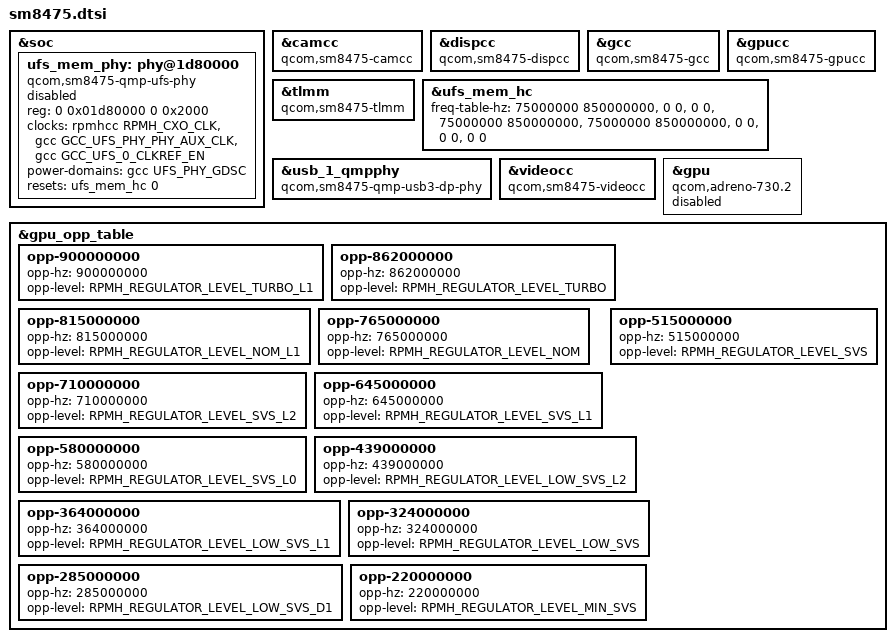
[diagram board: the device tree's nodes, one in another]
// SPDX-License-Identifier: BSD-3-Clause
/*
 * Copyright (c) 2024, Danila Tikhonov <danila@jiaxyga.com>
 *
 * Reconciled with upstream SM8450 support for Motorola Cape (SM8475).
 * Community reference: sm8450-mainline/linux bf1d29fced6e156dd6090a9b6600a8c44259c114
 * Motorola reference: kernel-devicetree 90fa7be1db5bd47202673d4431408659149a7359
 */

#include "sm8450.dtsi"

/*
 * Motorola's Cape UFS PHY is at 0x01d80000 rather than the
 * SM8450 PHY address inherited from sm8450.dtsi.
 */
/delete-node/ &ufs_mem_phy;

&soc {
	ufs_mem_phy: phy@1d80000 {
		compatible = "qcom,sm8475-qmp-ufs-phy";
		reg = <0 0x01d80000 0 0x2000>;

		clocks = <&rpmhcc RPMH_CXO_CLK>,
			 <&gcc GCC_UFS_PHY_PHY_AUX_CLK>,
			 <&gcc GCC_UFS_0_CLKREF_EN>;
		clock-names = "ref", "ref_aux", "qref";

		power-domains = <&gcc UFS_PHY_GDSC>;

		resets = <&ufs_mem_hc 0>;
		reset-names = "ufsphy";

		#clock-cells = <1>;
		#phy-cells = <0>;

		status = "disabled";
	};
};

&camcc {
	compatible = "qcom,sm8475-camcc";
};

&dispcc {
	compatible = "qcom,sm8475-dispcc";
};

&gcc {
	compatible = "qcom,sm8475-gcc";
};

&gpucc {
	compatible = "qcom,sm8475-gpucc";
};

/*
 * [INFERRED] Basic GPIO/UART muxing is compatible with SM8450.
 * Motorola's Cape pin mapping and PDC wake map were compared with the
 * upstream SM8450 driver; their complete alternate mux lists differ.
 * Keep the fallback only for initial board bring-up. Recheck before
 * enabling more pinctrl clients.
 */
&tlmm {
	compatible = "qcom,sm8475-tlmm", "qcom,sm8450-tlmm";
};

&ufs_mem_hc {
	freq-table-hz =
		<75000000 850000000>,
		<0 0>,
		<0 0>,
		<75000000 850000000>,
		<75000000 850000000>,
		<0 0>,
		<0 0>,
		<0 0>;
};

/* The baseline driver has an SM8475-specific USB3/DP PHY match. */
&usb_1_qmpphy {
	compatible = "qcom,sm8475-qmp-usb3-dp-phy";
};

&videocc {
	compatible = "qcom,sm8475-videocc";
};

/*
 * GPU OPPs for Motorola Cape / SM8475.
 *
 * The inherited SM8450 table has twelve entries. Ten frequencies are
 * SM8450-only, while the 220 MHz child also has a different voltage
 * corner. Remove the old entries before merging the thirteen Motorola
 * frequencies. Keep GPU disabled until GMU/CX vote mapping and signed
 * board firmware have been validated.
 *
 * Source: MotorolaMobilityLLC/kernel-devicetree
 * 90fa7be1db5bd47202673d4431408659149a7359 qcom/cape-gpu.dtsi
 * Proposed by GPU owner: Drzet/razr2022_nuc issue #4.
 * [INFERRED] Translating Motorola's GPU qcom,level to the upstream
 * RPMh opp-level is suitable; distinct CX votes are not represented.
 */
&gpu {
	compatible = "qcom,adreno-730.2", "qcom,adreno";
	status = "disabled";
};

&gpu_opp_table {
	/delete-node/ opp-818000000;
	/delete-node/ opp-791000000;
	/delete-node/ opp-734000000;
	/delete-node/ opp-640000000;
	/delete-node/ opp-599000000;
	/delete-node/ opp-545000000;
	/delete-node/ opp-492000000;
	/delete-node/ opp-421000000;
	/delete-node/ opp-350000000;
	/delete-node/ opp-317000000;

	opp-900000000 {
		opp-hz = /bits/ 64 <900000000>;
		opp-level = <RPMH_REGULATOR_LEVEL_TURBO_L1>;
	};
	opp-862000000 {
		opp-hz = /bits/ 64 <862000000>;
		opp-level = <RPMH_REGULATOR_LEVEL_TURBO>;
	};
	opp-815000000 {
		opp-hz = /bits/ 64 <815000000>;
		opp-level = <RPMH_REGULATOR_LEVEL_NOM_L1>;
	};
	opp-765000000 {
		opp-hz = /bits/ 64 <765000000>;
		opp-level = <RPMH_REGULATOR_LEVEL_NOM>;
	};
	opp-710000000 {
		opp-hz = /bits/ 64 <710000000>;
		opp-level = <RPMH_REGULATOR_LEVEL_SVS_L2>;
	};
	opp-645000000 {
		opp-hz = /bits/ 64 <645000000>;
		opp-level = <RPMH_REGULATOR_LEVEL_SVS_L1>;
	};
	opp-580000000 {
		opp-hz = /bits/ 64 <580000000>;
		opp-level = <RPMH_REGULATOR_LEVEL_SVS_L0>;
	};
	opp-515000000 {
		opp-hz = /bits/ 64 <515000000>;
		opp-level = <RPMH_REGULATOR_LEVEL_SVS>;
	};
	opp-439000000 {
		opp-hz = /bits/ 64 <439000000>;
		opp-level = <RPMH_REGULATOR_LEVEL_LOW_SVS_L2>;
	};
	opp-364000000 {
		opp-hz = /bits/ 64 <364000000>;
		opp-level = <RPMH_REGULATOR_LEVEL_LOW_SVS_L1>;
	};
	opp-324000000 {
		opp-hz = /bits/ 64 <324000000>;
		opp-level = <RPMH_REGULATOR_LEVEL_LOW_SVS>;
	};
	opp-285000000 {
		opp-hz = /bits/ 64 <285000000>;
		opp-level = <RPMH_REGULATOR_LEVEL_LOW_SVS_D1>;
	};
	opp-220000000 {
		opp-hz = /bits/ 64 <220000000>;
		opp-level = <RPMH_REGULATOR_LEVEL_MIN_SVS>;
	};
};

/*
 * Deliberate deferrals:
 * - SM8475 eUSB2 PHY/repeater supplies need a separate USB handoff.
 * - GPU OPPs are staged but disabled: CX votes, GMU profile and signed
 *   Motorola firmware still require independent validation.
 */
